# DEBUGSS_WRAP_CORTEX4_CFG_1_000740002B00h register map
Vendor: Texas Instruments
Peripheral module from a debugger description file (folder am62L).
Registers are 32-bit, read-write, reset 0x0 unless marked. A register's access mark holds for its fields unless they carry their own. Offsets are as the file gives them; lines under a group give offsets from that group; [hi:lo] are bit positions; {n}, {i} and the like mark numbered series; 'fields as' and 'values as' point back to an identical list; <NAME> marks a mode.

## cortex4_cfg_1
0x00 cortex4_cfg_1_CSWREG access per field — This register contains the Addressing control bit
  [4] ADDR_INC rw — Address Increment Enable
0x04 cortex4_cfg_1_TAREG access not given reset not defined — This register contains the address to write to or read from.
0x0C cortex4_cfg_1_DRWREG — This register is used to write data to the TA location or read it back from the TA location.
  [31:0] DATA_READ_WRITE_REGISTER — This register is used to read or write data
{0x10+4i} cortex4_cfg_1_BD{i}REG (i=0..3) — This register is used to transfer data when doing banked data operations.
  [31:0] BANKED_DATA_{i}_REGISTER — This register is used to transfer data when doing banked data operations
0xF8 cortex4_cfg_1_ROM_Register ro — Reading this register returns the AHB ROM Address.
  [31:0] ROM_REGISTER — Reading this register returns the ROM Address
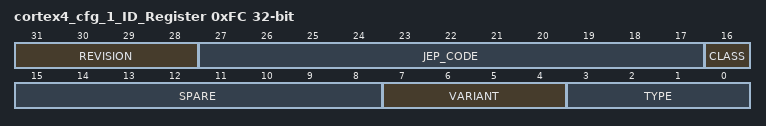
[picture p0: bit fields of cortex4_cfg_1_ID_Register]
0xFC cortex4_cfg_1_ID_Register ro — Reading this register returns the ID information for this AP.
  [31:28] REVISION — Device Revision [4]
  [27:17] JEP_CODE — Device JEP Code [0x23B]
  [16] CLASS — Device Class[1] [a memory access port]
  [15:8] SPARE — Spare, returns 0
  [7:4] VARIANT — Device Variant [1]
  [3:0] TYPE — Device Type: 0=JTAG, 1=AHB, 2=APB [1]
